# AT91SAM9M11 register map
Vendor: Atmel; File version: 20130207
CPU: 
Registers are 32-bit, read-write, no defined reset value unless marked. A register's access mark holds for its fields unless they carry their own. Offsets are from the block's base; [hi:lo] are bit positions; {n}, {i} and the like mark numbered series.

## LCDC — LCD Controller
Base 0x00500000
0x00 DMABADDR1 reset 0x0 — DMA Base Address Register 1
  [31:2] BADDR_U
0x04 DMABADDR2 reset 0x0 — DMA Base Address Register 2
  [31:0] BADDR_L
0x08 DMAFRMPT1 ro reset 0x0 — DMA Frame Pointer Register 1
  [22:0] FRMPT_U
0x0C DMAFRMPT2 ro reset 0x0 — DMA Frame Pointer Register 2
  [22:0] FRMPT_L
0x10 DMAFRMADD1 ro reset 0x0 — DMA Frame Address Register 1
  [31:0] FRMADD_U
0x14 DMAFRMADD2 ro reset 0x0 — DMA Frame Address Register 2
  [31:0] FRMADD_L
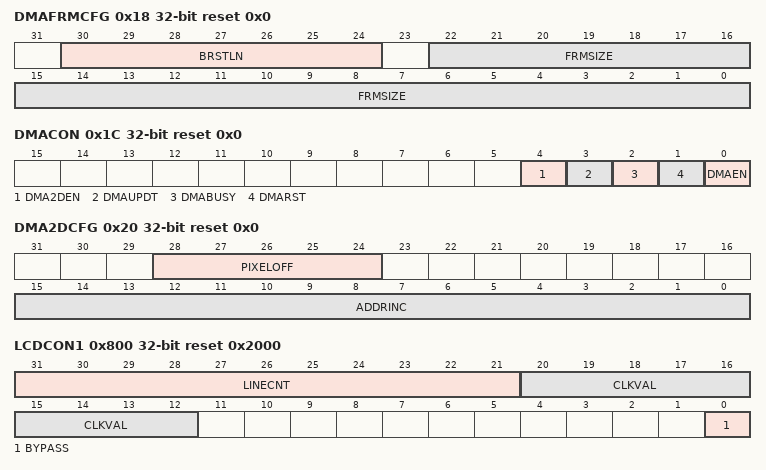
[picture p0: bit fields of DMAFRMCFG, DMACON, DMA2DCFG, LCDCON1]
0x18 DMAFRMCFG reset 0x0 — DMA Frame Configuration Register
  [30:24] BRSTLN — Burst Length in Words
  [22:0] FRMSIZE — Frame Size
0x1C DMACON reset 0x0 — DMA Control Register
  [4] DMA2DEN — DMA 2D Addressing Enable
  [3] DMAUPDT — DMA Configuration Update
  [2] DMABUSY
  [1] DMARST — DMA Reset (Write-only)
  [0] DMAEN — DMA Enable
0x20 DMA2DCFG reset 0x0 — DMA Control Register
  [28:24] PIXELOFF — DAM2D Addressing Pixel offset
  [15:0] ADDRINC — DMA 2D Addressing Address increment
0x800 LCDCON1 reset 0x2000 — LCD Control Register 1
  [31:21] LINECNT — Line Counter (Read-only)
  [20:12] CLKVAL — Clock Divider
  [0] BYPASS — Bypass LCDDOTCK Divider
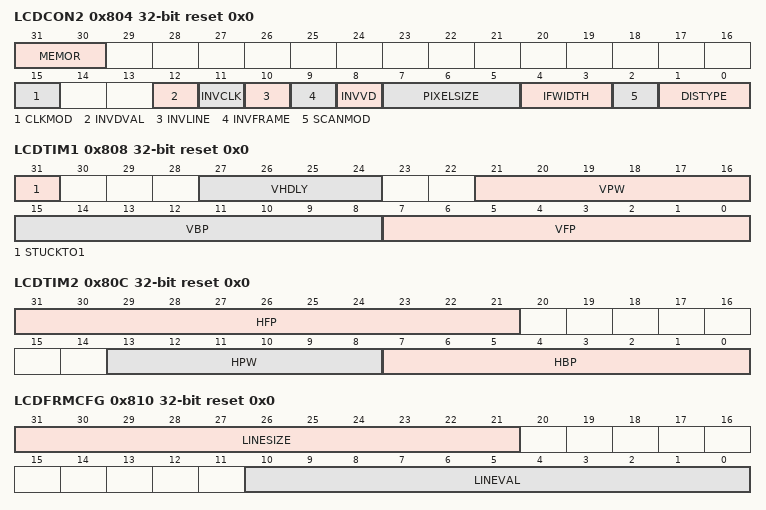
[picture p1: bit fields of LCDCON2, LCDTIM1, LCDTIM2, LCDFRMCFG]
0x804 LCDCON2 reset 0x0 — LCD Control Register 2
  [31:30] MEMOR — Memory Ordering Format
  [15] CLKMOD — LCDDOTCK mode
  [12] INVDVAL — LCDDEN polarity
  [11] INVCLK — LCDDOTCK polarity
  [10] INVLINE — LCDHSYNC polarity
  [9] INVFRAME — LCDVSYNC polarity
  [8] INVVD — LCDD polarity
  [7:5] PIXELSIZE — Bits per pixel
  [4:3] IFWIDTH — Interface width (STN)
  [2] SCANMOD — Scan Mode
  [1:0] DISTYPE — Display Type
0x808 LCDTIM1 reset 0x0 — LCD Timing Register 1
  [31] STUCKTO1
  [27:24] VHDLY — Vertical to horizontal delay
  [21:16] VPW — Vertical Synchronization pulse width
  [15:8] VBP — Vertical Back Porch
  [7:0] VFP — Vertical Front Porch
0x80C LCDTIM2 reset 0x0 — LCD Timing Register 2
  [31:21] HFP — Horizontal Front Porch
  [13:8] HPW — Horizontal synchronization pulse width
  [7:0] HBP — Horizontal Back Porch
0x810 LCDFRMCFG reset 0x0 — LCD Frame Configuration Register
  [31:21] LINESIZE — Horizontal size of LCD module, in pixels, minus 1
  [10:0] LINEVAL — Vertical size of LCD module
0x814 LCDFIFO reset 0x0
  [15:0] FIFOTH — FIFO Threshold
0x81C DP1_2 reset 0xA5 — Dithering Pattern DP1_2
  [7:0] DP1_2 — Pattern value for half duty cycle
0x820 DP4_7 reset 0x5AF0FA5 — Dithering Pattern DP4_7
  [27:0] DP4_7 — Pattern value for 4/7 duty cycle
0x824 DP3_5 reset 0xA5A5F — Dithering Pattern DP3_5
  [19:0] DP3_5 — Pattern value for 3/5 duty cycle
0x828 DP2_3 reset 0xA5F — Dithering Pattern DP2_3
  [11:0] DP2_3 — Pattern value for 2/3 duty cycle
0x82C DP5_7 reset 0xFAF5FA5 — Dithering Pattern DP5_7
  [27:0] DP5_7 — Pattern value for 5/7 duty cycle
0x830 DP3_4 reset 0xFAF5 — Dithering Pattern DP3_4
  [15:0] DP3_4 — Pattern value for 3/4 duty cycle
0x834 DP4_5 reset 0xFAF5F — Dithering Pattern DP4_5
  [19:0] DP4_5 — Pattern value for 4/5 duty cycle
0x838 DP6_7 reset 0xF5FFAFF — Dithering Pattern DP6_7
  [27:0] DP6_7 — Pattern value for 6/7 duty cycle
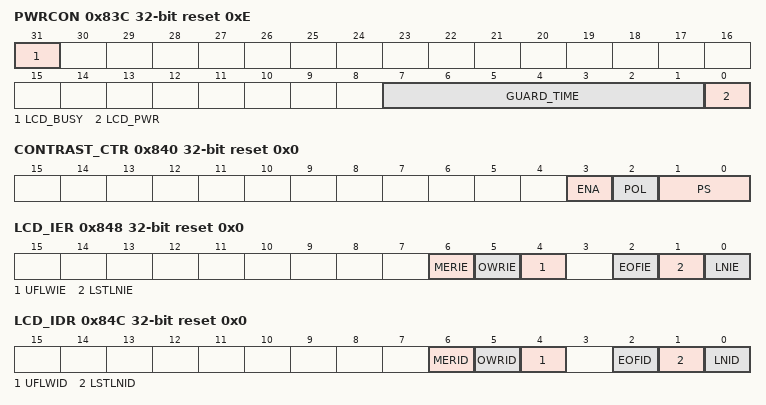
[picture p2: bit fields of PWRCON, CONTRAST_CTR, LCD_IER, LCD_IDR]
0x83C PWRCON reset 0xE — Power Control Register
  [31] LCD_BUSY
  [7:1] GUARD_TIME
  [0] LCD_PWR — LCD module power control
0x840 CONTRAST_CTR reset 0x0 — Contrast Control Register
  [3] ENA, [2] POL, [1:0] PS
0x844 CONTRAST_VAL reset 0x0 — Contrast Value Register
0x848 LCD_IER wo reset 0x0 — LCD Interrupt Enable Register
  [6] MERIE — DMA memory error interrupt enable
  [5] OWRIE — FIFO overwrite interrupt enable
  [4] UFLWIE — FIFO underflow interrupt enable
  [2] EOFIE — DMA End of frame interrupt enable
  [1] LSTLNIE — Last line interrupt enable
  [0] LNIE — Line interrupt enable
0x84C LCD_IDR wo reset 0x0 — LCD Interrupt Disable Register
  [6] MERID — DMA Memory error interrupt disable
  [5] OWRID — FIFO overwrite interrupt disable
  [4] UFLWID — FIFO underflow interrupt disable
  [2] EOFID — DMA End of frame interrupt disable
  [1] LSTLNID — Last line interrupt disable
  [0] LNID — Line interrupt disable
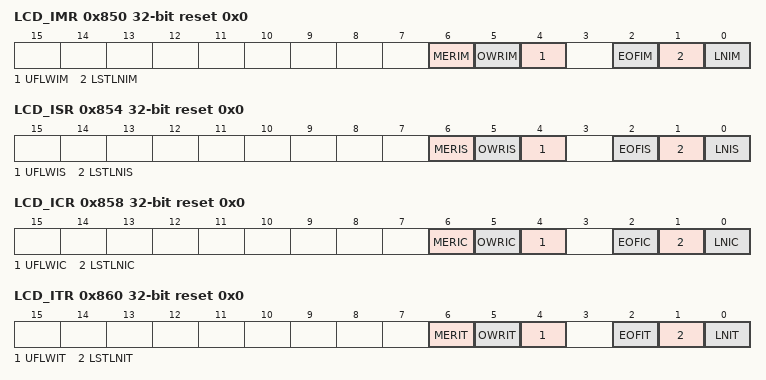
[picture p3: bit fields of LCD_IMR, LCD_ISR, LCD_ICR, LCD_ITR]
0x850 LCD_IMR ro reset 0x0 — LCD Interrupt Mask Register
  [6] MERIM — DMA Memory error interrupt mask
  [5] OWRIM — FIFO overwrite interrupt mask
  [4] UFLWIM — FIFO underflow interrupt mask
  [2] EOFIM — DMA End of frame interrupt mask
  [1] LSTLNIM — Last line interrupt mask
  [0] LNIM — Line interrupt mask
0x854 LCD_ISR ro reset 0x0 — LCD Interrupt Status Register
  [6] MERIS — DMA Memory error interrupt status
  [5] OWRIS — FIFO overwrite interrupt status
  [4] UFLWIS — FIFO underflow interrupt status
  [2] EOFIS — DMA End of frame interrupt status
  [1] LSTLNIS — Last line interrupt status
  [0] LNIS — Line interrupt status
0x858 LCD_ICR wo reset 0x0 — LCD Interrupt Clear Register
  [6] MERIC — DMA Memory error interrupt clear
  [5] OWRIC — FIFO overwrite interrupt clear
  [4] UFLWIC — FIFO underflow interrupt clear
  [2] EOFIC — DMA End of frame interrupt clear
  [1] LSTLNIC — Last line interrupt clear
  [0] LNIC — Line interrupt clear
0x860 LCD_ITR wo reset 0x0 — LCD Interrupt Test Register
  [6] MERIT — DMA Memory error interrupt test
  [5] OWRIT — FIFO overwrite interrupt test
  [4] UFLWIT — FIFO underflow interrupt test
  [2] EOFIT — DMA End of frame interrupt test
  [1] LSTLNIT — Last line interrupt test
  [0] LNIT — Line interrupt test
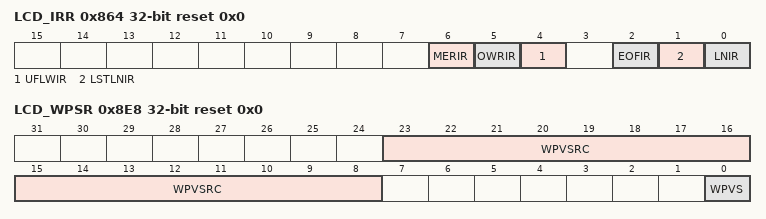
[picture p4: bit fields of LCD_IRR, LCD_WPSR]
0x864 LCD_IRR ro reset 0x0 — LCD Interrupt Raw Status Register
  [6] MERIR — DMA Memory error interrupt raw status
  [5] OWRIR — FIFO overwrite interrupt raw status
  [4] UFLWIR — FIFO underflow interrupt raw status
  [2] EOFIR — DMA End of frame interrupt raw status
  [1] LSTLNIR — Last line interrupt raw status
  [0] LNIR — Line interrupt raw status
0x8E4 LCD_WPCR reset 0x0 — Write Protection Control Register
0x8E8 LCD_WPSR ro reset 0x0 — Write Protection Status Register
  [23:8] WPVSRC — Write Protect Violation Source
  [0] WPVS — Write Protect Enable
{0xC00+4i} LUTENTRY[{i}] (i=0..255) — Palette entry
